# WS53 register map
File version: 0.1.0-experimental
Registers are 32-bit, read-write, no defined reset value unless marked. A register's access mark holds for its fields unless they carry their own. Offsets are from the block's base; [hi:lo] are bit positions.

## SDIO
Base 0x52060000
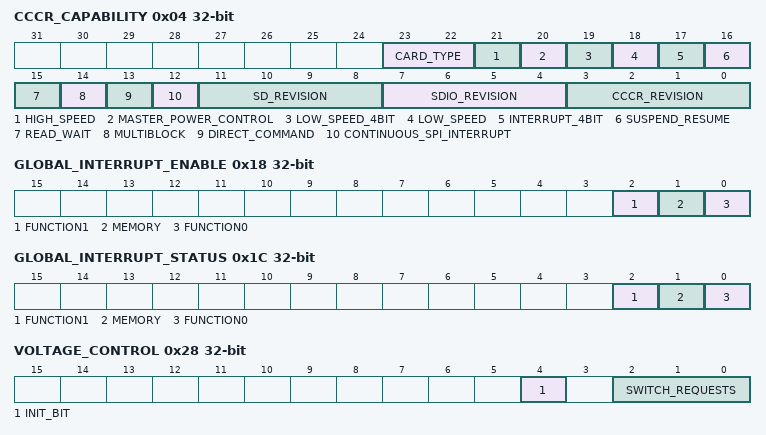
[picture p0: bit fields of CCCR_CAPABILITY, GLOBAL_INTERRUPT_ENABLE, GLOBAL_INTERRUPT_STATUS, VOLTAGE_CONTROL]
0x04 CCCR_CAPABILITY wo — Device capability configuration, not the host-side CCCR address space
  [23:22] CARD_TYPE, [21] HIGH_SPEED, [20] MASTER_POWER_CONTROL, [19] LOW_SPEED_4BIT, [18] LOW_SPEED, [17] INTERRUPT_4BIT, [16] SUSPEND_RESUME, [15] READ_WAIT, [14] MULTIBLOCK, [13] DIRECT_COMMAND, [12] CONTINUOUS_SPI_INTERRUPT, [11:8] SD_REVISION, [7:4] SDIO_REVISION, [3:0] CCCR_REVISION
0x18 GLOBAL_INTERRUPT_ENABLE
  [2] FUNCTION1, [1] MEMORY, [0] FUNCTION0
0x1C GLOBAL_INTERRUPT_STATUS ro
  [2] FUNCTION1, [1] MEMORY, [0] FUNCTION0
0x1C GLOBAL_INTERRUPT_ACK wo (alternate view of GLOBAL_INTERRUPT_STATUS) — ROM writes the captured status to acknowledge. Exact clear semantics not silicon tested; separate command view prevents RMW
  [31:0] VALUE
0x24 MODE — Opaque mode configuration: ROM sets bits 0..6, meanings not established by an available register header
  [6:0] INIT_PROFILE — ROM sets this entire seven-bit profile; individual meanings unknown
0x28 VOLTAGE_CONTROL — ROM initialization sets bit 4; voltage-switch routine sets bits 0..2. Electrical sequencing remains unverified
  [4] INIT_BIT — Bit set by ROM base initialization, not a voltage-ready indication
  [2:0] SWITCH_REQUESTS
0x2C CONFIG_2C — Opaque configuration: ROM reads then writes 0x2f92 during initialization
  [31:0] VALUE
0x30 CONFIG_30 — Opaque configuration: ROM sets bit 0 after registering the IRQ
  [0] INIT_BIT — ROM sets after common configuration; no completion semantics inferred
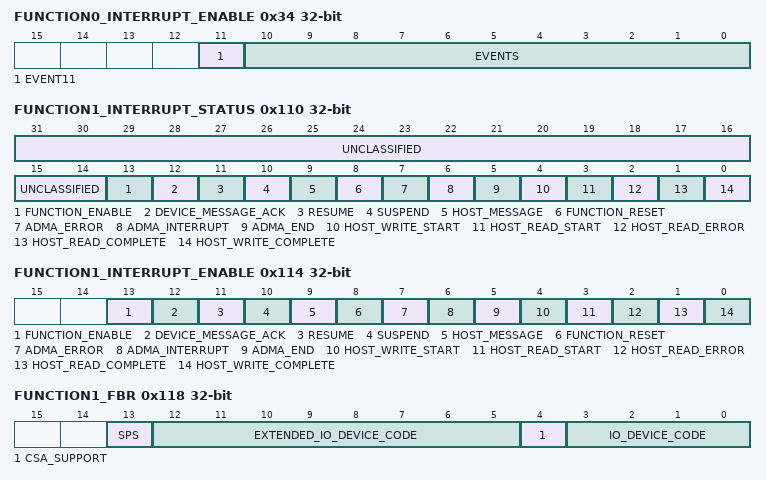
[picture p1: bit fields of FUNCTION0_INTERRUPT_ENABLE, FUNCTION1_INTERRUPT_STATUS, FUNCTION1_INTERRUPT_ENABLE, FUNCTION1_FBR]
0x34 FUNCTION0_INTERRUPT_ENABLE — ROM enables bits 0..11; individual event semantics not fully established. The last orshf rotates 16 right by 25, producing 0x800, not bit16
  [11] EVENT11, [10:0] EVENTS
0x38 FUNCTION0_INTERRUPT_STATUS ro
  [31:0] VALUE
0x38 FUNCTION0_INTERRUPT_ACK wo (alternate view of FUNCTION0_INTERRUPT_STATUS) — Captured-status acknowledgement command; no automatic RMW or inferred W1C/reset values
  [31:0] VALUE
0x3C FUNCTION0_RESET_STATUS ro
  [31:0] VALUE
0x3C FUNCTION0_RESET_COMMAND wo (alternate view of FUNCTION0_RESET_STATUS) — ROM writes readback OR 1 during function0 reset handling; completion/self-clear semantics unknown
  [31:0] VALUE
0x40 ADMA_TABLE wo — ROM submits an 8-byte-stride ADMA table here after the host read/write callback. Starts bus-master access; not a software-only pointer
  [31:0] ADDRESS
0x44 HOST_CLOCK ro
  [0] READY
0x104 FUNCTION1_SEND_STATUS ro
  [31:0] VALUE
0x104 FUNCTION1_SEND_COMMAND wo (alternate view of FUNCTION1_SEND_STATUS) — ROM writes readback OR 1 after setting send length; self-clear behavior unspecified
  [31:0] VALUE
0x10C FUNCTION1_CONFIG — Opaque function1 configuration: ROM replaces low 24 bits with 0xff8000
  [23:0] INIT_PROFILE
0x110 FUNCTION1_INTERRUPT_STATUS ro — ROM function1 callback/counter event mapping; status does not prove ADMA drain
  [31:14] UNCLASSIFIED, [13] FUNCTION_ENABLE, [12] DEVICE_MESSAGE_ACK, [11] RESUME, [10] SUSPEND, [9] HOST_MESSAGE, [8] FUNCTION_RESET, [7] ADMA_ERROR, [6] ADMA_INTERRUPT, [5] ADMA_END, [4] HOST_WRITE_START, [3] HOST_READ_START, [2] HOST_READ_ERROR, [1] HOST_READ_COMPLETE, [0] HOST_WRITE_COMPLETE
0x110 FUNCTION1_INTERRUPT_ACK wo (alternate view of FUNCTION1_INTERRUPT_STATUS) — Captured-status acknowledgement command; no automatic RMW or inferred W1C/reset values
  [31:0] VALUE
0x114 FUNCTION1_INTERRUPT_ENABLE — ROM enables all fourteen mapped function1 events; no inferred reset or completion semantics
  [13] FUNCTION_ENABLE, [12] DEVICE_MESSAGE_ACK, [11] RESUME, [10] SUSPEND, [9] HOST_MESSAGE, [8] FUNCTION_RESET, [7] ADMA_ERROR, [6] ADMA_INTERRUPT, [5] ADMA_END, [4] HOST_WRITE_START, [3] HOST_READ_START, [2] HOST_READ_ERROR, [1] HOST_READ_COMPLETE, [0] HOST_WRITE_COMPLETE
0x118 FUNCTION1_FBR
  [13] SPS, [12:5] EXTENDED_IO_DEVICE_CODE, [4] CSA_SUPPORT, [3:0] IO_DEVICE_CODE
0x11C FUNCTION1_READY — ROM sets bit 0 after function enable interrupt and polls it during init
  [0] READY
0x120 FUNCTION1_SEND_LENGTH
  [20:0] BYTES
0x128 HOST_MESSAGE ro
  [31:0] VALUE
0x12C DEVICE_MESSAGE wo — ROM writes a device-to-host message. No modify API; message delivery/acknowledgement requires protocol ownership
  [31:0] VALUE
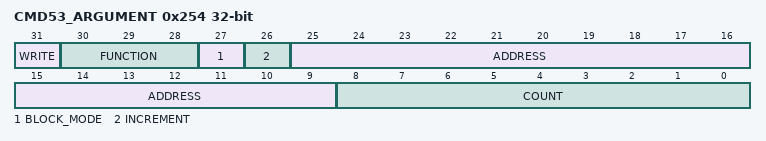
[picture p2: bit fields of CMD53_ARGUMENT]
0x254 CMD53_ARGUMENT ro
  [31] WRITE, [30:28] FUNCTION, [27] BLOCK_MODE, [26] INCREMENT, [25:9] ADDRESS, [8:0] COUNT
0x258 FUNCTION1_BLOCK_SIZE ro
  [11:0] BYTES
